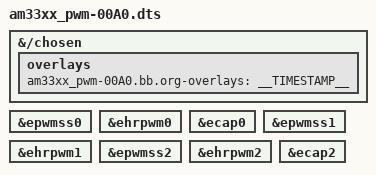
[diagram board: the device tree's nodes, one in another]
// SPDX-License-Identifier: GPL-2.0-only
/*
 * Copyright (C) 2013 CircuitCo
 * Copyright (C) 2013 Texas Instruments Incorporated - https://www.ti.com/
 */

/dts-v1/;
/plugin/;

/*
 * Helper to show loaded overlays under: /proc/device-tree/chosen/overlays/
 */
&{/chosen} {
	overlays {
		am33xx_pwm-00A0.bb.org-overlays = __TIMESTAMP__;
	};
};

/ {
	fragment@1 {
		target = <&epwmss0>;
		__overlay__ {
			status = "okay";
		};
	};

	fragment@2 {
		target = <&ehrpwm0>;
		__overlay__ {
			status = "okay";
		};
	};

	fragment@3 {
		target = <&ecap0>;
		__overlay__ {
			status = "okay";
		};
	};

	fragment@4 {
		target = <&epwmss1>;
		__overlay__ {
			status = "okay";
		};
	};

	fragment@5 {
		target = <&ehrpwm1>;
		__overlay__ {
			status = "okay";
		};
	};

	fragment@6 {
		target = <&epwmss2>;
		__overlay__ {
			status = "okay";
		};
	};

	fragment@7 {
		target = <&ehrpwm2>;
		__overlay__ {
			status = "okay";
		};
	};

	fragment@8 {
		target = <&ecap2>;
		__overlay__ {
			status = "okay";
		};
	};
};
